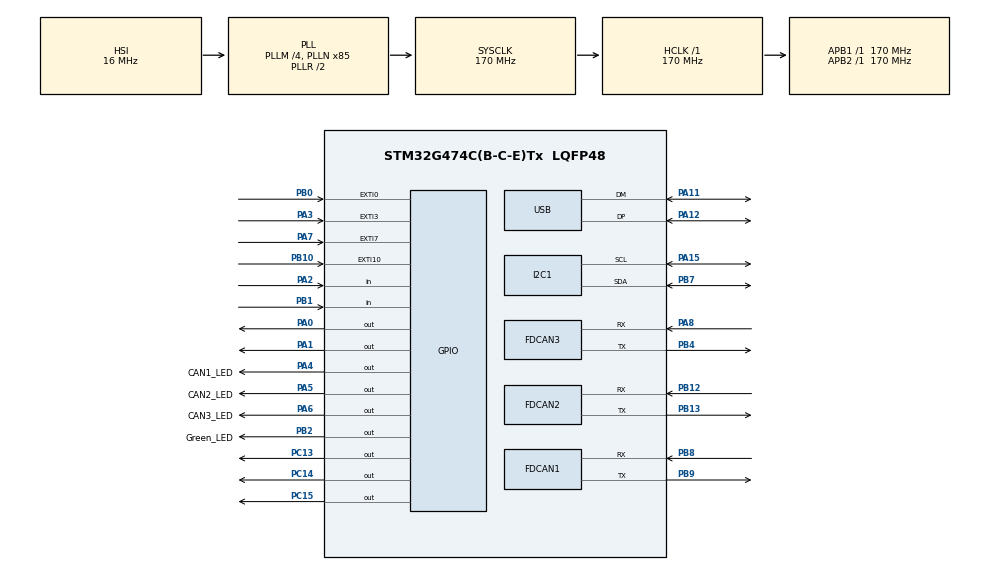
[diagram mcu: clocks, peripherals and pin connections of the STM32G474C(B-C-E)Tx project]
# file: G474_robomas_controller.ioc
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FDCAN1.AutoRetransmission=ENABLE
FDCAN1.CalculateBaudRateNominal=999999
FDCAN1.CalculateTimeBitNominal=1000
FDCAN1.CalculateTimeQuantumNominal=58.82352941176471
FDCAN1.NominalPrescaler=10
FDCAN1.NominalSyncJumpWidth=3
FDCAN1.NominalTimeSeg1=13
FDCAN1.NominalTimeSeg2=3
FDCAN1.StdFiltersNbr=1
FDCAN2.AutoRetransmission=ENABLE
FDCAN2.CalculateBaudRateNominal=999999
FDCAN2.CalculateTimeBitNominal=1000
FDCAN2.CalculateTimeQuantumNominal=58.82352941176471
FDCAN2.NominalPrescaler=10
FDCAN2.NominalTimeSeg1=13
FDCAN2.NominalTimeSeg2=3
FDCAN2.StdFiltersNbr=1
FDCAN3.AutoRetransmission=ENABLE
FDCAN3.CalculateBaudRateNominal=999999
FDCAN3.CalculateTimeBitNominal=1000
FDCAN3.CalculateTimeQuantumNominal=58.82352941176471
FDCAN3.NominalPrescaler=10
FDCAN3.NominalTimeSeg1=13
FDCAN3.NominalTimeSeg2=3
FDCAN3.StdFiltersNbr=1
I2C1.Timing=0x40B285C2
Mcu.Family=STM32G4
Mcu.Name=STM32G474C(B-C-E)Tx
Mcu.Package=LQFP48
NVIC.EXTI0_IRQn=true\:0\:0\:false\:false\:true\:true\:true\:true
NVIC.EXTI15_10_IRQn=true\:0\:0\:false\:false\:true\:true\:true\:true
NVIC.EXTI3_IRQn=true\:0\:0\:false\:false\:true\:true\:true\:true
NVIC.FDCAN1_IT0_IRQn=true\:0\:0\:false\:false\:true\:true\:true\:true
NVIC.FDCAN2_IT0_IRQn=true\:0\:0\:false\:false\:true\:true\:true\:true
NVIC.FDCAN3_IT0_IRQn=true\:0\:0\:false\:false\:true\:true\:true\:true
NVIC.PriorityGroup=NVIC_PRIORITYGROUP_4
NVIC.TIM6_DAC_IRQn=true\:0\:0\:false\:false\:true\:true\:true\:true
NVIC.USB_LP_IRQn=true\:0\:0\:false\:false\:true\:false\:true\:true
PA0.Signal=GPIO_Output
PA1.Signal=GPIO_Output
PA11.Mode=Device
PA11.Signal=USB_DM
PA12.Mode=Device
PA12.Signal=USB_DP
PA13.Mode=Serial_Wire
PA13.Signal=SYS_JTMS-SWDIO
PA14.Mode=Serial_Wire
PA14.Signal=SYS_JTCK-SWCLK
PA15.Mode=I2C
PA15.Signal=I2C1_SCL
PA2.GPIO_PuPd=GPIO_PULLUP
PA2.Signal=GPIO_Input
PA3.GPIO_PuPd=GPIO_PULLUP
PA3.Signal=GPXTI3
PA4.GPIO_Label=CAN1_LED
PA4.Signal=GPIO_Output
PA5.GPIO_Label=CAN2_LED
PA5.Signal=GPIO_Output
PA6.GPIO_Label=CAN3_LED
PA6.Signal=GPIO_Output
PA7.Signal=GPXTI7
PA8.Mode=FDCAN_Activate
PA8.Signal=FDCAN3_RX
PB0.GPIO_ModeDefaultEXTI=GPIO_MODE_IT_RISING_FALLING
PB0.GPIO_PuPd=GPIO_PULLUP
PB0.Signal=GPXTI0
PB1.GPIO_PuPd=GPIO_PULLUP
PB1.Signal=GPIO_Input
PB10.GPIO_PuPd=GPIO_PULLUP
PB10.Signal=GPXTI10
PB12.Mode=FDCAN_Activate
PB12.Signal=FDCAN2_RX
PB13.Mode=FDCAN_Activate
PB13.Signal=FDCAN2_TX
PB2.GPIO_Label=Green_LED
PB2.Signal=GPIO_Output
PB4.Mode=FDCAN_Activate
PB4.Signal=FDCAN3_TX
PB7.Mode=I2C
PB7.Signal=I2C1_SDA
PB8-BOOT0.Mode=FDCAN_Activate
PB8-BOOT0.Signal=FDCAN1_RX
PB9.Mode=FDCAN_Activate
PB9.Signal=FDCAN1_TX
PC13.GPIO_PuPd=GPIO_PULLDOWN
PC13.Signal=GPIO_Output
PC14-OSC32_IN.GPIO_PuPd=GPIO_PULLDOWN
PC14-OSC32_IN.Signal=GPIO_Output
PC15-OSC32_OUT.GPIO_PuPd=GPIO_PULLDOWN
PC15-OSC32_OUT.Signal=GPIO_Output
ProjectManager.HeapSize=0x200
ProjectManager.StackSize=0x400
ProjectManager.TargetToolchain=STM32CubeIDE
RCC.ADC12Freq_Value=170000000
RCC.ADC345Freq_Value=170000000
RCC.AHBFreq_Value=170000000
RCC.APB1Freq_Value=170000000
RCC.APB1TimFreq_Value=170000000
RCC.APB2Freq_Value=170000000
RCC.APB2TimFreq_Value=170000000
RCC.CK48CLockSelection=RCC_USBCLKSOURCE_HSI48
RCC.CortexFreq_Value=170000000
RCC.EXTERNAL_CLOCK_VALUE=12288000
RCC.HCLKFreq_Value=170000000
RCC.HSE_VALUE=8000000
RCC.HSI48_VALUE=48000000
RCC.HSI_VALUE=16000000
RCC.LSE_VALUE=32768
RCC.PLLM=RCC_PLLM_DIV4
RCC.PLLN=85
RCC.SYSCLKFreq_VALUE=170000000
RCC.SYSCLKSource=RCC_SYSCLKSOURCE_PLLCLK
RCC.USBFreq_Value=48000000
RCC.VCOOutputFreq_Value=340000000
TIM6.PeriodNoDither=9999
TIM6.Prescaler=169
USB_DEVICE.CLASS_NAME_FS=CDC
USB_DEVICE.VirtualMode=Cdc
USB_DEVICE.VirtualModeFS=Cdc_FS
VP_SYS_VS_DBSignals.Mode=DisableDeadBatterySignals
VP_TIM6_VS_ClockSourceINT.Mode=Enable_Timer
VP_USB_DEVICE_VS_USB_DEVICE_CDC_FS.Mode=CDC_FS
board=custom

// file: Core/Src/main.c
/* USER CODE BEGIN Header */
/**
  ******************************************************************************
  * @file           : main.c
  * @brief          : Main program body
  ******************************************************************************
  * @attention
  *
  * Copyright (c) 2026 STMicroelectronics.
  * All rights reserved.
  *
  * This software is licensed under terms that can be found in the LICENSE file
  * in the root directory of this software component.
  * If no LICENSE file comes with this software, it is provided AS-IS.
  *
  ******************************************************************************
  */
/* USER CODE END Header */
#include "main.h"
#include "fdcan.h"
#include "i2c.h"
#include "tim.h"
#include "usb_device.h"
#include "gpio.h"

/* USER CODE BEGIN Includes */
#include "app.hpp"
/* USER CODE END Includes */

void SystemClock_Config(void);

int main(void)
{

  /* MCU Configuration--------------------------------------------------------*/

  /* Reset of all peripherals, Initializes the Flash interface and the Systick. */
  HAL_Init();

  /* Configure the system clock */
  SystemClock_Config();

  /* Initialize all configured peripherals */
  MX_GPIO_Init();
  MX_FDCAN1_Init();
  MX_FDCAN2_Init();
  MX_FDCAN3_Init();
  MX_I2C1_Init();
  MX_TIM6_Init();
  MX_USB_Device_Init();
  /* USER CODE BEGIN 2 */
  App_Init();
  /* USER CODE END 2 */

  /* Infinite loop */
  /* USER CODE BEGIN WHILE */
  while (1)
  {
	  App_Loop();
    /* USER CODE END WHILE */

  }
}

void SystemClock_Config(void)
{
  RCC_OscInitTypeDef RCC_OscInitStruct = {0};
  RCC_ClkInitTypeDef RCC_ClkInitStruct = {0};

  /** Configure the main internal regulator output voltage
  */
  HAL_PWREx_ControlVoltageScaling(PWR_REGULATOR_VOLTAGE_SCALE1_BOOST);

  /** Initializes the RCC Oscillators according to the specified parameters
  * in the RCC_OscInitTypeDef structure.
  */
  RCC_OscInitStruct.OscillatorType = RCC_OSCILLATORTYPE_HSI|RCC_OSCILLATORTYPE_HSI48;
  RCC_OscInitStruct.HSIState = RCC_HSI_ON;
  RCC_OscInitStruct.HSICalibrationValue = RCC_HSICALIBRATION_DEFAULT;
  RCC_OscInitStruct.HSI48State = RCC_HSI48_ON;
  RCC_OscInitStruct.PLL.PLLState = RCC_PLL_ON;
  RCC_OscInitStruct.PLL.PLLSource = RCC_PLLSOURCE_HSI;
  RCC_OscInitStruct.PLL.PLLM = RCC_PLLM_DIV4;
  RCC_OscInitStruct.PLL.PLLN = 85;
  RCC_OscInitStruct.PLL.PLLP = RCC_PLLP_DIV2;
  RCC_OscInitStruct.PLL.PLLQ = RCC_PLLQ_DIV2;
  RCC_OscInitStruct.PLL.PLLR = RCC_PLLR_DIV2;
  if (HAL_RCC_OscConfig(&RCC_OscInitStruct) != HAL_OK)
  {
    Error_Handler();
  }

  /** Initializes the CPU, AHB and APB buses clocks
  */
  RCC_ClkInitStruct.ClockType = RCC_CLOCKTYPE_HCLK|RCC_CLOCKTYPE_SYSCLK
                              |RCC_CLOCKTYPE_PCLK1|RCC_CLOCKTYPE_PCLK2;
  RCC_ClkInitStruct.SYSCLKSource = RCC_SYSCLKSOURCE_PLLCLK;
  RCC_ClkInitStruct.AHBCLKDivider = RCC_SYSCLK_DIV1;
  RCC_ClkInitStruct.APB1CLKDivider = RCC_HCLK_DIV1;
  RCC_ClkInitStruct.APB2CLKDivider = RCC_HCLK_DIV1;

  if (HAL_RCC_ClockConfig(&RCC_ClkInitStruct, FLASH_LATENCY_4) != HAL_OK)
  {
    Error_Handler();
  }
}

void Error_Handler(void)
{
  __disable_irq();
  while (1)
  {
  }
}
